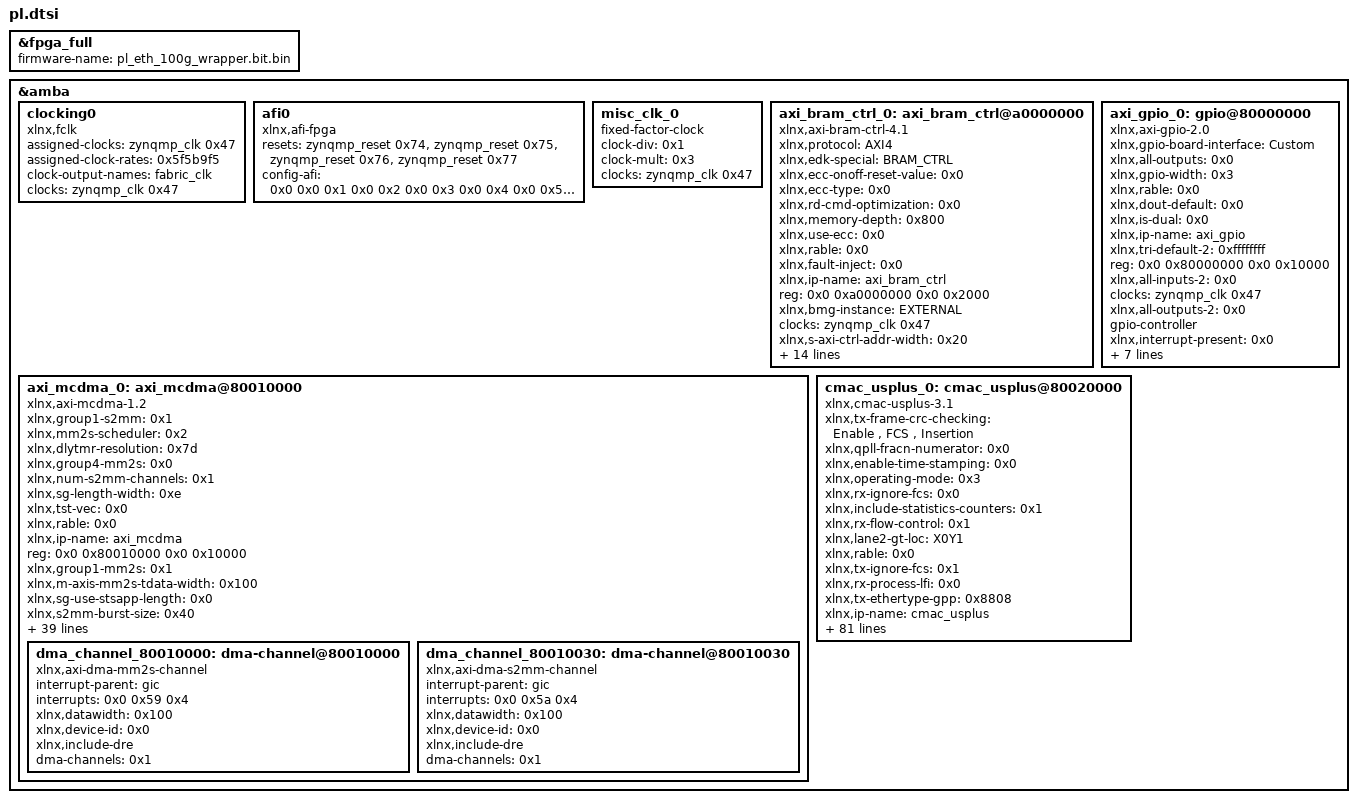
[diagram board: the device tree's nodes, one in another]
/dts-v1/;
/plugin/;
&fpga_full{
	firmware-name = "pl_eth_100g_wrapper.bit.bin";
};
&amba{
	clocking0: clocking0 {
		compatible = "xlnx,fclk";
		status = "okay";
		assigned-clocks = <&zynqmp_clk 0x47>;
		assigned-clock-rates = <0x5f5b9f5>;
		#clock-cells = <0x0>;
		clock-output-names = "fabric_clk";
		clocks = <&zynqmp_clk 0x47>;
	};
	afi0: afi0 {
		status = "okay";
		compatible = "xlnx,afi-fpga";
		resets = <&zynqmp_reset 0x74>,
<&zynqmp_reset 0x75>,
<&zynqmp_reset 0x76>,
<&zynqmp_reset 0x77>;
		config-afi = <0x0 0x0 0x1 0x0 0x2 0x0 0x3 0x0 0x4 0x0 0x5 0x0 0x6 0x0 0x7 0x0 0x8 0x0 0x9 0x0 0xa 0x0 0xb 0x0 0xc 0x0 0xd 0x0 0xe 0x800 0xf 0x0>;
	};
};
&amba{
	misc_clk_0: misc_clk_0 {
		clock-div = <0x1>;
		compatible = "fixed-factor-clock";
		clock-mult = <0x3>;
		clocks = <&zynqmp_clk 0x47>;
		#clock-cells = <0x0>;
	};
	axi_bram_ctrl_0: axi_bram_ctrl@a0000000 {
		xlnx,protocol = "AXI4";
		xlnx,edk-special = "BRAM_CTRL";
		compatible = "xlnx,axi-bram-ctrl-4.1";
		xlnx,ecc-onoff-reset-value = <0x0>;
		xlnx,ecc-type = <0x0>;
		xlnx,rd-cmd-optimization = <0x0>;
		xlnx,memory-depth = <0x800>;
		xlnx,use-ecc = <0x0>;
		xlnx,rable = <0x0>;
		xlnx,fault-inject = <0x0>;
		xlnx,ip-name = "axi_bram_ctrl";
		reg = <0x0 0xa0000000 0x0 0x2000>;
		xlnx,bmg-instance = "EXTERNAL";
		clocks = <&zynqmp_clk 0x47>;
		xlnx,s-axi-ctrl-addr-width = <0x20>;
		xlnx,read-latency = <0x1>;
		xlnx,id-width = <0x10>;
		xlnx,s-axi-supports-narrow-burst = <0x1>;
		xlnx,supports-narrow-burst = <0x1>;
		xlnx,single-port-bram = <0x0>;
		xlnx,ecc = <0x0>;
		xlnx,edk-iptype = "PERIPHERAL";
		status = "okay";
		clock-names = "s_axi_aclk";
		xlnx,data-width = <0x20>;
		xlnx,bram-addr-width = <0xb>;
		xlnx,bram-inst-mode = "EXTERNAL";
		xlnx,s-axi-ctrl-data-width = <0x20>;
		xlnx,mem-depth = <0x800>;
		xlnx,s-axi-id-width = <0x10>;
		xlnx,name = "axi_bram_ctrl_0";
	};
	axi_gpio_0: gpio@80000000 {
		xlnx,gpio-board-interface = "Custom";
		compatible = "xlnx,axi-gpio-2.0", "xlnx,xps-gpio-1.00.a";
		xlnx,all-outputs = <0x0>;
		#gpio-cells = <0x2>;
		xlnx,gpio-width = <0x3>;
		xlnx,rable = <0x0>;
		xlnx,dout-default = <0x0>;
		xlnx,is-dual = <0x0>;
		xlnx,ip-name = "axi_gpio";
		xlnx,tri-default-2 = <0xffffffff>;
		reg = <0x0 0x80000000 0x0 0x10000>;
		xlnx,all-inputs-2 = <0x0>;
		clocks = <&zynqmp_clk 0x47>;
		xlnx,all-outputs-2 = <0x0>;
		gpio-controller;
		xlnx,interrupt-present = <0x0>;
		xlnx,gpio2-board-interface = "Custom";
		xlnx,edk-iptype = "PERIPHERAL";
		xlnx,dout-default-2 = <0x0>;
		status = "okay";
		xlnx,gpio2-width = <0x20>;
		clock-names = "s_axi_aclk";
		xlnx,tri-default = <0xffffffff>;
		xlnx,name = "axi_gpio_0";
		xlnx,all-inputs = <0x1>;
	};
	axi_mcdma_0: axi_mcdma@80010000 {
		xlnx,group1-s2mm = <0x1>;
		xlnx,mm2s-scheduler = <0x2>;
		xlnx,dlytmr-resolution = <0x7d>;
		xlnx,group4-mm2s = <0x0>;
		xlnx,num-s2mm-channels = <0x1>;
		xlnx,sg-length-width = <0xe>;
		xlnx,tst-vec = <0x0>;
		xlnx,rable = <0x0>;
		xlnx,ip-name = "axi_mcdma";
		reg = <0x0 0x80010000 0x0 0x10000>;
		xlnx,group1-mm2s = <0x1>;
		xlnx,m-axis-mm2s-tdata-width = <0x100>;
		xlnx,sg-use-stsapp-length = <0x0>;
		xlnx,s2mm-burst-size = <0x40>;
		xlnx,num-mm2s-channels = <0x1>;
		xlnx,group6-s2mm = <0x0>;
		interrupt-names = "mm2s_ch1_introut", "s2mm_ch1_introut";
		xlnx,enable-single-intr = <0x0>;
		xlnx,enable-multi-intr = <0x1>;
		compatible = "xlnx,axi-mcdma-1.2", "xlnx,axi-mcdma-1.00.a";
		xlnx,group3-s2mm = <0x0>;
		xlnx,mm2s-burst-size = <0x40>;
		interrupt-parent = <&gic>;
		xlnx,enable-multi-ch-reset = <0x0>;
		xlnx,group6-mm2s = <0x0>;
		xlnx,include-s2mm-dre = <0x1>;
		xlnx,group3-mm2s = <0x0>;
		xlnx,m-axi-s2mm-data-width = <0x200>;
		xlnx,support-cyclic-bd = <0x0>;
		status = "okay";
		xlnx,include-mm2s-dre = <0x1>;
		xlnx,name = "axi_mcdma_0";
		interrupts = <0x0 0x59 0x4 0x0 0x5a 0x4>;
		xlnx,m-axi-mm2s-data-width = <0x200>;
		xlnx,ethernet-dma = <0x0>;
		xlnx,group5-s2mm = <0x0>;
		xlnx,include-s2mm-sf = <0x1>;
		xlnx,addr-width = <0x20>;
		xlnx,include-s2mm = <0x1>;
		xlnx,single-interface = <0x0>;
		clocks = <&misc_clk_0>,
<&misc_clk_0>,
<&misc_clk_0>,
<&zynqmp_clk 0x47>;
		xlnx,s-axis-s2mm-tdata-width = <0x100>;
		xlnx,addrwidth = [20];
		xlnx,group2-s2mm = <0x0>;
		xlnx,include-dre;
		xlnx,edk-iptype = "PERIPHERAL";
		xlnx,group5-mm2s = <0x0>;
		xlnx,include-mm2s-sf = <0x1>;
		clock-names = "m_axi_mm2s_aclk", "m_axi_s2mm_aclk", "m_axi_sg_aclk", "s_axi_lite_aclk";
		xlnx,include-mm2s = <0x1>;
		xlnx,s2mm-data-width = <0x200>;
		xlnx,group2-mm2s = <0x0>;
		xlnx,prmry-is-aclk-async = <0x1>;
		#dma-cells = <0x1>;
		xlnx,sg-include-stscntrl-strm = <0x0>;
		xlnx,mm2s-data-width = <0x200>;
		xlnx,group4-s2mm = <0x0>;
	
		dma_channel_80010000: dma-channel@80010000 {
			interrupt-parent = <&gic>;
			interrupts = <0x0 0x59 0x4>;
			xlnx,datawidth = <0x100>;
			xlnx,device-id = <0x0>;
			compatible = "xlnx,axi-dma-mm2s-channel";
			xlnx,include-dre;
			dma-channels = <0x1>;
		};
		dma_channel_80010030: dma-channel@80010030 {
			interrupt-parent = <&gic>;
			interrupts = <0x0 0x5a 0x4>;
			xlnx,datawidth = <0x100>;
			xlnx,device-id = <0x0>;
			compatible = "xlnx,axi-dma-s2mm-channel";
			xlnx,include-dre;
			dma-channels = <0x1>;
		};
		};
	cmac_usplus_0: cmac_usplus@80020000 {
		xlnx,tx-frame-crc-checking = "Enable , FCS , Insertion";
		xlnx,qpll-fracn-numerator = <0x0>;
		xlnx,enable-time-stamping = <0x0>;
		xlnx,operating-mode = <0x3>;
		xlnx,rx-ignore-fcs = <0x0>;
		xlnx,include-statistics-counters = <0x1>;
		xlnx,rx-flow-control = <0x1>;
		xlnx,lane2-gt-loc = "X0Y1";
		xlnx,rable = <0x0>;
		xlnx,tx-ignore-fcs = <0x1>;
		xlnx,rx-process-lfi = <0x0>;
		xlnx,tx-ethertype-gpp = <0x8808>;
		xlnx,ip-name = "cmac_usplus";
		reg = <0x0 0x80020000 0x0 0x10000>;
		xlnx,enable-axis = <0x0>;
		xlnx,add-gt-cnrl-sts-ports = <0x0>;
		xlnx,include-auto-neg-lt-logic = <0x0>;
		xlnx,line-rate = <0x1896402>;
		xlnx,gt-group-select = <0x0>;
		xlnx,rx-delete-fcs = <0x1>;
		xlnx,enable-axi-interface = <0x1>;
		xlnx,lane1-gt-loc = "X0Y0";
		xlnx,rx-forward-control-frames = <0x0>;
		xlnx,diffclk-board-interface = "Custom";
		xlnx,fast-sim-mode = <0x0>;
		xlnx,tx-sa-ppp = <0x0>;
		xlnx,tx-da-gpp = <0x180 0xc2000001>;
		compatible = "xlnx,cmac-usplus-3.1";
		xlnx,gt-type = "GTY";
		xlnx,rx-opcode-gpp = <0x1>;
		xlnx,rx-pause-sa = <0x0>;
		xlnx,tx-opcode-gpp = <0x1>;
		xlnx,exdes-axi4lite-interface = <0x0>;
		xlnx,tx-ptp-vlane-adjust-mode = <0x0>;
		xlnx,rx-check-preamble = <0x0>;
		xlnx,rx-etype-gpp = <0x8808>;
		xlnx,include-shared-logic = <0x2>;
		xlnx,rx-pause-da-mcast = <0x180 0xc2000001>;
		xlnx,family-chk = "zynquplus";
		xlnx,rx-max-packet-len = <0x2580>;
		status = "okay";
		xlnx,use-board-flow;
		xlnx,pll-type = "QPLL0";
		xlnx,rs-fec-transcode-bypass = <0x0>;
		xlnx,tx-fcs-ins-enable = <0x1>;
		xlnx,tx-ethertype-ppp = <0x8808>;
		xlnx,tx-lane0-vlm-bip7-override = <0x0>;
		xlnx,rx-opcode-min-gcp = <0x0>;
		xlnx,name = "cmac_usplus_0";
		xlnx,rx-opcode-max-gcp = <0xffff>;
		xlnx,rx-pause-da-ucast = <0x0>;
		xlnx,clocking-mode = "Asynchronous";
		xlnx,is-board-project = <0x1>;
		xlnx,enable-pipeline-reg = <0x0>;
		xlnx,ptp-transpclk-mode = <0x0>;
		xlnx,rx-etype-gcp = <0x8808>;
		xlnx,tx-flow-control = <0x1>;
		xlnx,gt-ref-clk-freq = <0x99ab10c>;
		xlnx,update-lt-coeff = <0x0>;
		xlnx,gt-rx-buffer-bypass = <0x0>;
		xlnx,include-an-lt-tx-trainer = <0x0>;
		xlnx,num-lanes = <0x4>;
		clocks = <&zynqmp_clk 0x47>,
<&zynqmp_clk 0x47>,
<&misc_clk_0>,
<&zynqmp_clk 0x47>;
		xlnx,cmac-caui4-mode = <0x1>;
		xlnx,gt-location = <0x1>;
		xlnx,rx-check-ack = <0x1>;
		xlnx,tx-da-ppp = <0x180 0xc2000001>;
		xlnx,edk-iptype = "PERIPHERAL";
		xlnx,rx-min-packet-len = <0x40>;
		xlnx,user-interface = "AXIS";
		xlnx,ins-loss-nyq = <0xc>;
		xlnx,rx-opcode-ppp = <0x101>;
		clock-names = "drp_clk", "init_clk", "rx_clk", "s_axi_aclk";
		xlnx,rx-check-sfd = <0x0>;
		xlnx,tx-opcode-ppp = <0x101>;
		xlnx,ethernet-board-interface = "Custom";
		xlnx,tx-ptp-latency-adjust = <0x0>;
		xlnx,rx-etype-ppp = <0x8808>;
		xlnx,gt-drp-clk = <0x64>;
		xlnx,cmac-core-select = "CMACE4_X0Y0";
		xlnx,lane4-gt-loc = "X0Y3";
		xlnx,rs-fec-core-sel = "CMACE4_X0Y0";
		xlnx,statistics-regs-type = <0x0>;
		xlnx,tx-sa-gpp = <0x0>;
		xlnx,include-rs-fec = <0x1>;
		xlnx,rx-opcode-min-pcp = <0x0>;
		xlnx,tx-ptp-1step-enable = <0x0>;
		xlnx,tx-ipg-value = <0xc>;
		xlnx,rx-opcode-max-pcp = <0xffff>;
		xlnx,lane3-gt-loc = "X0Y2";
		xlnx,rx-etype-pcp = <0x8808>;
		xlnx,rx-eq-mode = "AUTO";
		xlnx,tx-otn-interface = <0x0>;
		xlnx,rx-frame-crc-checking = "Enable , FCS , Stripping";
		xlnx,rx-gt-buffer = <0x1>;
	};
};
